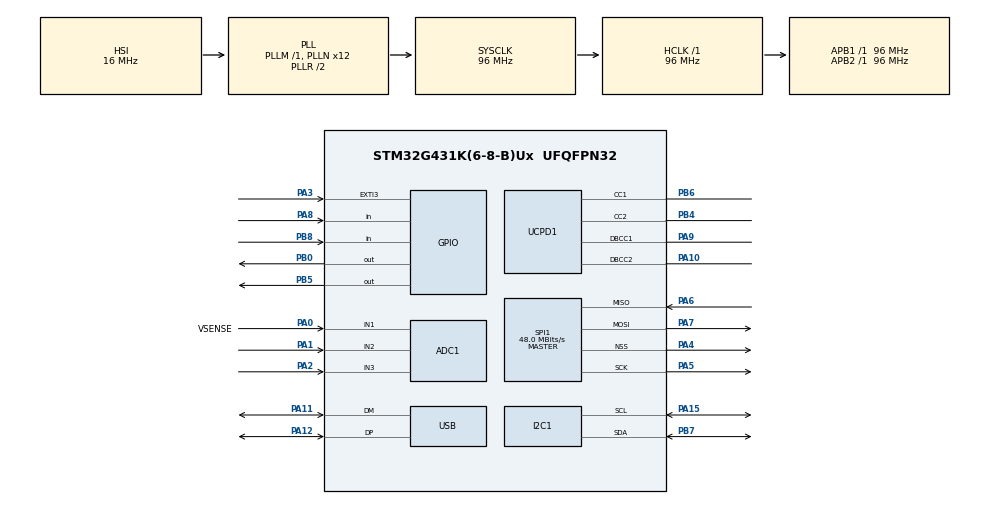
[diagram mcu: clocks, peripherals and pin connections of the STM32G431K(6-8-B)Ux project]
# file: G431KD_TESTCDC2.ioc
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ADC1.Channel-0\#ChannelRegularConversion=ADC_CHANNEL_1
ADC1.ClockPrescaler=ADC_CLOCK_SYNC_PCLK_DIV4
ADC1.ContinuousConvMode=ENABLE
ADC1.NbrOfConversion=1
ADC1.NbrOfConversionFlag=1
ADC1.OffsetNumber-0\#ChannelRegularConversion=ADC_OFFSET_NONE
ADC1.Overrun=ADC_OVR_DATA_OVERWRITTEN
ADC1.Rank-0\#ChannelRegularConversion=1
ADC1.SamplingTime-0\#ChannelRegularConversion=ADC_SAMPLETIME_247CYCLES_5
ADC1.master=1
Dma.ADC1.0.Direction=DMA_PERIPH_TO_MEMORY
Dma.ADC1.0.EventEnable=DISABLE
Dma.ADC1.0.Instance=DMA1_Channel3
Dma.ADC1.0.MemDataAlignment=DMA_MDATAALIGN_HALFWORD
Dma.ADC1.0.MemInc=DMA_MINC_ENABLE
Dma.ADC1.0.Mode=DMA_NORMAL
Dma.ADC1.0.PeriphDataAlignment=DMA_PDATAALIGN_HALFWORD
Dma.ADC1.0.PeriphInc=DMA_PINC_DISABLE
Dma.ADC1.0.Polarity=HAL_DMAMUX_REQ_GEN_RISING
Dma.ADC1.0.Priority=DMA_PRIORITY_LOW
Dma.ADC1.0.RequestNumber=1
Dma.ADC1.0.SignalID=NONE
Dma.ADC1.0.SyncEnable=DISABLE
Dma.ADC1.0.SyncPolarity=HAL_DMAMUX_SYNC_NO_EVENT
Dma.ADC1.0.SyncRequestNumber=1
Dma.ADC1.0.SyncSignalID=NONE
Dma.I2C1_RX.5.Direction=DMA_PERIPH_TO_MEMORY
Dma.I2C1_RX.5.EventEnable=DISABLE
Dma.I2C1_RX.5.Instance=DMA2_Channel1
Dma.I2C1_RX.5.MemDataAlignment=DMA_MDATAALIGN_BYTE
Dma.I2C1_RX.5.MemInc=DMA_MINC_ENABLE
Dma.I2C1_RX.5.Mode=DMA_NORMAL
Dma.I2C1_RX.5.PeriphDataAlignment=DMA_PDATAALIGN_BYTE
Dma.I2C1_RX.5.PeriphInc=DMA_PINC_DISABLE
Dma.I2C1_RX.5.Polarity=HAL_DMAMUX_REQ_GEN_RISING
Dma.I2C1_RX.5.Priority=DMA_PRIORITY_LOW
Dma.I2C1_RX.5.RequestNumber=1
Dma.I2C1_RX.5.SignalID=NONE
Dma.I2C1_RX.5.SyncEnable=DISABLE
Dma.I2C1_RX.5.SyncPolarity=HAL_DMAMUX_SYNC_NO_EVENT
Dma.I2C1_RX.5.SyncRequestNumber=1
Dma.I2C1_RX.5.SyncSignalID=NONE
Dma.I2C1_TX.6.Direction=DMA_MEMORY_TO_PERIPH
Dma.I2C1_TX.6.EventEnable=DISABLE
Dma.I2C1_TX.6.Instance=DMA2_Channel2
Dma.I2C1_TX.6.MemDataAlignment=DMA_MDATAALIGN_BYTE
Dma.I2C1_TX.6.MemInc=DMA_MINC_ENABLE
Dma.I2C1_TX.6.Mode=DMA_NORMAL
Dma.I2C1_TX.6.PeriphDataAlignment=DMA_PDATAALIGN_BYTE
Dma.I2C1_TX.6.PeriphInc=DMA_PINC_DISABLE
Dma.I2C1_TX.6.Polarity=HAL_DMAMUX_REQ_GEN_RISING
Dma.I2C1_TX.6.Priority=DMA_PRIORITY_LOW
Dma.I2C1_TX.6.RequestNumber=1
Dma.I2C1_TX.6.SignalID=NONE
Dma.I2C1_TX.6.SyncEnable=DISABLE
Dma.I2C1_TX.6.SyncPolarity=HAL_DMAMUX_SYNC_NO_EVENT
Dma.I2C1_TX.6.SyncRequestNumber=1
Dma.I2C1_TX.6.SyncSignalID=NONE
Dma.Request0=ADC1
Dma.Request1=UCPD1_RX
Dma.Request2=UCPD1_TX
Dma.Request3=SPI1_RX
Dma.Request4=SPI1_TX
Dma.Request5=I2C1_RX
Dma.Request6=I2C1_TX
Dma.SPI1_RX.3.Direction=DMA_PERIPH_TO_MEMORY
Dma.SPI1_RX.3.EventEnable=DISABLE
Dma.SPI1_RX.3.Instance=DMA1_Channel4
Dma.SPI1_RX.3.MemDataAlignment=DMA_MDATAALIGN_BYTE
Dma.SPI1_RX.3.MemInc=DMA_MINC_ENABLE
Dma.SPI1_RX.3.Mode=DMA_NORMAL
Dma.SPI1_RX.3.PeriphDataAlignment=DMA_PDATAALIGN_BYTE
Dma.SPI1_RX.3.PeriphInc=DMA_PINC_DISABLE
Dma.SPI1_RX.3.Polarity=HAL_DMAMUX_REQ_GEN_RISING
Dma.SPI1_RX.3.Priority=DMA_PRIORITY_LOW
Dma.SPI1_RX.3.RequestNumber=1
Dma.SPI1_RX.3.SignalID=NONE
Dma.SPI1_RX.3.SyncEnable=DISABLE
Dma.SPI1_RX.3.SyncPolarity=HAL_DMAMUX_SYNC_NO_EVENT
Dma.SPI1_RX.3.SyncRequestNumber=1
Dma.SPI1_RX.3.SyncSignalID=NONE
Dma.SPI1_TX.4.Direction=DMA_MEMORY_TO_PERIPH
Dma.SPI1_TX.4.EventEnable=DISABLE
Dma.SPI1_TX.4.Instance=DMA1_Channel5
Dma.SPI1_TX.4.MemDataAlignment=DMA_MDATAALIGN_BYTE
Dma.SPI1_TX.4.MemInc=DMA_MINC_ENABLE
Dma.SPI1_TX.4.Mode=DMA_NORMAL
Dma.SPI1_TX.4.PeriphDataAlignment=DMA_PDATAALIGN_BYTE
Dma.SPI1_TX.4.PeriphInc=DMA_PINC_DISABLE
Dma.SPI1_TX.4.Polarity=HAL_DMAMUX_REQ_GEN_RISING
Dma.SPI1_TX.4.Priority=DMA_PRIORITY_LOW
Dma.SPI1_TX.4.RequestNumber=1
Dma.SPI1_TX.4.SignalID=NONE
Dma.SPI1_TX.4.SyncEnable=DISABLE
Dma.SPI1_TX.4.SyncPolarity=HAL_DMAMUX_SYNC_NO_EVENT
Dma.SPI1_TX.4.SyncRequestNumber=1
Dma.SPI1_TX.4.SyncSignalID=NONE
Dma.UCPD1_RX.1.Direction=DMA_PERIPH_TO_MEMORY
Dma.UCPD1_RX.1.EventEnable=DISABLE
Dma.UCPD1_RX.1.Instance=DMA1_Channel1
Dma.UCPD1_RX.1.MemDataAlignment=DMA_MDATAALIGN_BYTE
Dma.UCPD1_RX.1.MemInc=DMA_MINC_ENABLE
Dma.UCPD1_RX.1.Mode=DMA_NORMAL
Dma.UCPD1_RX.1.PeriphDataAlignment=DMA_PDATAALIGN_BYTE
Dma.UCPD1_RX.1.PeriphInc=DMA_PINC_DISABLE
Dma.UCPD1_RX.1.Polarity=HAL_DMAMUX_REQ_GEN_RISING
Dma.UCPD1_RX.1.Priority=DMA_PRIORITY_LOW
Dma.UCPD1_RX.1.RequestNumber=1
Dma.UCPD1_RX.1.SignalID=NONE
Dma.UCPD1_RX.1.SyncEnable=DISABLE
Dma.UCPD1_RX.1.SyncPolarity=HAL_DMAMUX_SYNC_NO_EVENT
Dma.UCPD1_RX.1.SyncRequestNumber=1
Dma.UCPD1_RX.1.SyncSignalID=NONE
Dma.UCPD1_TX.2.Direction=DMA_MEMORY_TO_PERIPH
Dma.UCPD1_TX.2.EventEnable=DISABLE
Dma.UCPD1_TX.2.Instance=DMA1_Channel2
Dma.UCPD1_TX.2.MemDataAlignment=DMA_MDATAALIGN_BYTE
Dma.UCPD1_TX.2.MemInc=DMA_MINC_ENABLE
Dma.UCPD1_TX.2.Mode=DMA_NORMAL
Dma.UCPD1_TX.2.PeriphDataAlignment=DMA_PDATAALIGN_BYTE
Dma.UCPD1_TX.2.PeriphInc=DMA_PINC_DISABLE
Dma.UCPD1_TX.2.Polarity=HAL_DMAMUX_REQ_GEN_RISING
Dma.UCPD1_TX.2.Priority=DMA_PRIORITY_LOW
Dma.UCPD1_TX.2.RequestNumber=1
Dma.UCPD1_TX.2.SignalID=NONE
Dma.UCPD1_TX.2.SyncEnable=DISABLE
Dma.UCPD1_TX.2.SyncPolarity=HAL_DMAMUX_SYNC_NO_EVENT
Dma.UCPD1_TX.2.SyncRequestNumber=1
Dma.UCPD1_TX.2.SyncSignalID=NONE
FREERTOS.Tasks01=defaultTask,24,128,StartDefaultTask,Default,NULL,Dynamic,NULL,NULL
FREERTOS.configTOTAL_HEAP_SIZE=0x1000
I2C1.Timing=0x10B0DCFB
Mcu.Family=STM32G4
Mcu.Name=STM32G431K(6-8-B)Ux
Mcu.Package=UFQFPN32
Mcu.UserConstants=VDDA_APPLI,3300
NVIC.DMA1_Channel1_IRQn=true\:0\:0\:false\:false\:true\:true\:false\:true
NVIC.DMA1_Channel2_IRQn=true\:0\:0\:false\:false\:true\:true\:false\:true
NVIC.DMA1_Channel3_IRQn=true\:0\:0\:false\:false\:true\:true\:false\:true
NVIC.DMA1_Channel4_IRQn=true\:0\:0\:false\:false\:true\:true\:false\:true
NVIC.DMA1_Channel5_IRQn=true\:0\:0\:false\:false\:true\:true\:false\:true
NVIC.DMA2_Channel1_IRQn=true\:0\:0\:false\:false\:true\:false\:false\:true
NVIC.DMA2_Channel2_IRQn=true\:0\:0\:false\:false\:true\:false\:false\:true
NVIC.PriorityGroup=NVIC_PRIORITYGROUP_4
NVIC.TIM8_UP_IRQn=true\:0\:0\:false\:false\:true\:false\:false\:true
NVIC.TimeBase=TIM8_UP_IRQn
NVIC.TimeBaseIP=TIM8
NVIC.UCPD1_IRQn=true\:0\:0\:false\:false\:true\:true\:true\:false
NVIC.USB_LP_IRQn=true\:0\:0\:false\:false\:true\:false\:false\:true
PA0.GPIO_Label=VSENSE
PA0.Mode=IN1-Single-Ended
PA0.Signal=ADC1_IN1
PA1.Mode=IN2-Single-Ended
PA1.Signal=ADC1_IN2
PA10.Mode=EnableDeadBattery
PA10.Signal=UCPD1_DBCC2
PA11.Mode=Device
PA11.Signal=USB_DM
PA12.Mode=Device
PA12.Signal=USB_DP
PA13.Mode=Trace_Asynchronous_SW
PA13.Signal=SYS_JTMS-SWDIO
PA14.Mode=Trace_Asynchronous_SW
PA14.Signal=SYS_JTCK-SWCLK
PA15.Mode=I2C
PA15.Signal=I2C1_SCL
PA2.Mode=IN3-Single-Ended
PA2.Signal=ADC1_IN3
PA3.Signal=GPXTI3
PA4.Mode=NSS_Signal_Hard_Output
PA4.Signal=SPI1_NSS
PA5.Mode=Full_Duplex_Master
PA5.Signal=SPI1_SCK
PA6.Mode=Full_Duplex_Master
PA6.Signal=SPI1_MISO
PA7.Mode=Full_Duplex_Master
PA7.Signal=SPI1_MOSI
PA8.GPIO_PuPd=GPIO_PULLUP
PA8.Signal=GPIO_Input
PA9.Mode=EnableDeadBattery
PA9.Signal=UCPD1_DBCC1
PB0.Signal=GPIO_Output
PB3.Mode=Trace_Asynchronous_SW
PB3.Signal=SYS_JTDO-SWO
PB4.Mode=Sink_AllSignals
PB4.Signal=UCPD1_CC2
PB5.Signal=GPIO_Output
PB6.Mode=Sink_AllSignals
PB6.Signal=UCPD1_CC1
PB7.Mode=I2C
PB7.Signal=I2C1_SDA
PB8-BOOT0.GPIO_PuPd=GPIO_PULLUP
PB8-BOOT0.Signal=GPIO_Input
PF0-OSC_IN.Mode=HSE-External-Oscillator
PF0-OSC_IN.Signal=RCC_OSC_IN
PF1-OSC_OUT.Mode=HSE-External-Oscillator
PF1-OSC_OUT.Signal=RCC_OSC_OUT
ProjectManager.HeapSize=0x400
ProjectManager.StackSize=0x400
ProjectManager.TargetToolchain=STM32CubeIDE
RCC.ADC12Freq_Value=96000000
RCC.AHBFreq_Value=96000000
RCC.APB1Freq_Value=96000000
RCC.APB1TimFreq_Value=96000000
RCC.APB2Freq_Value=96000000
RCC.APB2TimFreq_Value=96000000
RCC.CK48CLockSelection=RCC_USBCLKSOURCE_HSI48
RCC.CortexFreq_Value=96000000
RCC.EXTERNAL_CLOCK_VALUE=12288000
RCC.HCLKFreq_Value=96000000
RCC.HSE_VALUE=24000000
RCC.HSI48_VALUE=48000000
RCC.HSI_VALUE=16000000
RCC.LSE_VALUE=32768
RCC.PLLN=12
RCC.PLLQ=RCC_PLLQ_DIV4
RCC.SYSCLKFreq_VALUE=96000000
RCC.SYSCLKSource=RCC_SYSCLKSOURCE_PLLCLK
RCC.USBFreq_Value=48000000
RCC.VCOOutputFreq_Value=192000000
SPI1.BaudRatePrescaler=SPI_BAUDRATEPRESCALER_2
SPI1.CalculateBaudRate=48.0 MBits/s
SPI1.Direction=SPI_DIRECTION_2LINES
SPI1.Mode=SPI_MODE_MASTER
SPI1.VirtualNSS=VM_NSSHARD
SPI1.VirtualType=VM_MASTER
USBPD.PE_SpecRevision_P0=USBPD_SPECIFICATION_REV3
USBPD.PE_SupportedSOPapos_P0=USBPD_SUPPORTED_SOP_SOP1
USBPD.PORT0_SINK_PDO1=0x02019096
USB_DEVICE.CLASS_NAME_FS=CDC
USB_DEVICE.PID_CDC_FS=0x5740
USB_DEVICE.USBD_DEBUG_LEVEL=3
USB_DEVICE.USBD_MAX_NUM_CONFIGURATION=1
USB_DEVICE.USBD_MAX_NUM_INTERFACES=1
USB_DEVICE.VID=0x483
USB_DEVICE.VirtualMode=Cdc
USB_DEVICE.VirtualModeFS=Cdc_FS
VP_ADC1_TempSens_Input.Mode=IN-TempSens
VP_FREERTOS_VS_CMSIS_V2.Mode=CMSIS_V2
VP_RTC_VS_RTC_Activate.Mode=RTC_Enabled
VP_SYS_VS_DBSignals.Mode=DisableDeadBatterySignals
VP_SYS_VS_tim8.Mode=TIM8
VP_SYS_V_PVD_IN.Mode=Mode_PVD_Int
VP_USBPD_VS_PD3MINSNK.Mode=PD3_Min_Snk
VP_USBPD_VS_USBPD1.Mode=USBPD_P0
VP_USBPD_VS_usbpd_tim1.Mode=TIM1
VP_USB_DEVICE_VS_USB_DEVICE_CDC_FS.Mode=CDC_FS
board=custom

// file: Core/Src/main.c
/* USER CODE BEGIN Header */
/**
  ******************************************************************************
  * @file           : main.c
  * @brief          : Main program body
  ******************************************************************************
  * @attention
  *
  * <h2><center>&copy; Copyright (c) 2020 STMicroelectronics.
  * All rights reserved.</center></h2>
  *
  * This software component is licensed by ST under Ultimate Liberty license
  * SLA0044, the "License"; You may not use this file except in compliance with
  * the License. You may obtain a copy of the License at:
  *                             www.st.com/SLA0044
  *
  ******************************************************************************
  */
/* USER CODE END Header */
#include "main.h"
#include "cmsis_os.h"
#include "usbpd.h"
#include "usb_device.h"

/* USER CODE BEGIN Includes */
// https://github.com/AlexKlimaj/LiPow-Firmware
// PD User manual: UM2552
// https://github.com/STMicroelectronics/STM32CubeG4/blob/master/Projects/STM32G474E-EVAL/Applications/USB-PD/USB-PD_Provider_1port/Src/usbpd_vdm_user.c
// https://github.com/STMicroelectronics/STM32CubeG4/blob/master/Projects/STM32G474E-EVAL/Demonstrations/Modules/ucpd/usbpd_dpm_user.h
/* USER CODE END Includes */

ADC_HandleTypeDef hadc1;
DMA_HandleTypeDef hdma_adc1;

I2C_HandleTypeDef hi2c1;
DMA_HandleTypeDef hdma_i2c1_rx;
DMA_HandleTypeDef hdma_i2c1_tx;

RTC_HandleTypeDef hrtc;

SPI_HandleTypeDef hspi1;
DMA_HandleTypeDef hdma_spi1_rx;
DMA_HandleTypeDef hdma_spi1_tx;

/* Definitions for defaultTask */
osThreadId_t defaultTaskHandle;
const osThreadAttr_t defaultTask_attributes = {
  .name = "defaultTask",
  .priority = (osPriority_t) osPriorityNormal,
  .stack_size = 128 * 4
};

void SystemClock_Config(void);
static void MX_GPIO_Init(void);
static void MX_DMA_Init(void);
static void MX_ADC1_Init(void);
static void MX_UCPD1_Init(void);
static void MX_SPI1_Init(void);
static void MX_I2C1_Init(void);
static void MX_RTC_Init(void);
void StartDefaultTask(void *argument);

int main(void)
{

  /* MCU Configuration--------------------------------------------------------*/

  /* Reset of all peripherals, Initializes the Flash interface and the Systick. */
  HAL_Init();

  /* Configure the system clock */
  SystemClock_Config();

  /* Initialize all configured peripherals */
  MX_GPIO_Init();
  MX_DMA_Init();
  MX_ADC1_Init();
  MX_UCPD1_Init();
  MX_SPI1_Init();
  MX_I2C1_Init();
  MX_RTC_Init();
  MX_USB_Device_Init();

  /* Init scheduler */
  osKernelInitialize();
  /* USBPD initialisation ---------------------------------*/
  MX_USBPD_Init();

  /* Create the thread(s) */
  /* creation of defaultTask */
  defaultTaskHandle = osThreadNew(StartDefaultTask, NULL, &defaultTask_attributes);

  /* Start scheduler */
  osKernelStart();

  /* We should never get here as control is now taken by the scheduler */
  /* Infinite loop */
  while (1)
  {

  }
}

void SystemClock_Config(void)
{
  RCC_OscInitTypeDef RCC_OscInitStruct = {0};
  RCC_ClkInitTypeDef RCC_ClkInitStruct = {0};
  RCC_PeriphCLKInitTypeDef PeriphClkInit = {0};

  /** Configure the main internal regulator output voltage
  */
  HAL_PWREx_ControlVoltageScaling(PWR_REGULATOR_VOLTAGE_SCALE1);
  /** Initializes the RCC Oscillators according to the specified parameters
  * in the RCC_OscInitTypeDef structure.
  */
  RCC_OscInitStruct.OscillatorType = RCC_OSCILLATORTYPE_HSI|RCC_OSCILLATORTYPE_HSI48
                              |RCC_OSCILLATORTYPE_LSI;
  RCC_OscInitStruct.HSIState = RCC_HSI_ON;
  RCC_OscInitStruct.HSICalibrationValue = RCC_HSICALIBRATION_DEFAULT;
  RCC_OscInitStruct.LSIState = RCC_LSI_ON;
  RCC_OscInitStruct.HSI48State = RCC_HSI48_ON;
  RCC_OscInitStruct.PLL.PLLState = RCC_PLL_ON;
  RCC_OscInitStruct.PLL.PLLSource = RCC_PLLSOURCE_HSI;
  RCC_OscInitStruct.PLL.PLLM = RCC_PLLM_DIV1;
  RCC_OscInitStruct.PLL.PLLN = 12;
  RCC_OscInitStruct.PLL.PLLP = RCC_PLLP_DIV2;
  RCC_OscInitStruct.PLL.PLLQ = RCC_PLLQ_DIV4;
  RCC_OscInitStruct.PLL.PLLR = RCC_PLLR_DIV2;
  if (HAL_RCC_OscConfig(&RCC_OscInitStruct) != HAL_OK)
  {
    Error_Handler();
  }
  /** Initializes the CPU, AHB and APB buses clocks
  */
  RCC_ClkInitStruct.ClockType = RCC_CLOCKTYPE_HCLK|RCC_CLOCKTYPE_SYSCLK
                              |RCC_CLOCKTYPE_PCLK1|RCC_CLOCKTYPE_PCLK2;
  RCC_ClkInitStruct.SYSCLKSource = RCC_SYSCLKSOURCE_PLLCLK;
  RCC_ClkInitStruct.AHBCLKDivider = RCC_SYSCLK_DIV1;
  RCC_ClkInitStruct.APB1CLKDivider = RCC_HCLK_DIV1;
  RCC_ClkInitStruct.APB2CLKDivider = RCC_HCLK_DIV1;

  if (HAL_RCC_ClockConfig(&RCC_ClkInitStruct, FLASH_LATENCY_2) != HAL_OK)
  {
    Error_Handler();
  }
  /** Initializes the peripherals clocks
  */
  PeriphClkInit.PeriphClockSelection = RCC_PERIPHCLK_RTC|RCC_PERIPHCLK_I2C1
                              |RCC_PERIPHCLK_USB|RCC_PERIPHCLK_ADC12;
  PeriphClkInit.I2c1ClockSelection = RCC_I2C1CLKSOURCE_PCLK1;
  PeriphClkInit.UsbClockSelection = RCC_USBCLKSOURCE_HSI48;
  PeriphClkInit.Adc12ClockSelection = RCC_ADC12CLKSOURCE_SYSCLK;
  PeriphClkInit.RTCClockSelection = RCC_RTCCLKSOURCE_LSI;

  if (HAL_RCCEx_PeriphCLKConfig(&PeriphClkInit) != HAL_OK)
  {
    Error_Handler();
  }
}

static void MX_ADC1_Init(void)
{

  ADC_MultiModeTypeDef multimode = {0};
  ADC_ChannelConfTypeDef sConfig = {0};

  /** Common config
  */
  hadc1.Instance = ADC1;
  hadc1.Init.ClockPrescaler = ADC_CLOCK_SYNC_PCLK_DIV4;
  hadc1.Init.Resolution = ADC_RESOLUTION_12B;
  hadc1.Init.DataAlign = ADC_DATAALIGN_RIGHT;
  hadc1.Init.GainCompensation = 0;
  hadc1.Init.ScanConvMode = ADC_SCAN_DISABLE;
  hadc1.Init.EOCSelection = ADC_EOC_SINGLE_CONV;
  hadc1.Init.LowPowerAutoWait = DISABLE;
  hadc1.Init.ContinuousConvMode = ENABLE;
  hadc1.Init.NbrOfConversion = 1;
  hadc1.Init.DiscontinuousConvMode = DISABLE;
  hadc1.Init.ExternalTrigConv = ADC_SOFTWARE_START;
  hadc1.Init.ExternalTrigConvEdge = ADC_EXTERNALTRIGCONVEDGE_NONE;
  hadc1.Init.DMAContinuousRequests = DISABLE;
  hadc1.Init.Overrun = ADC_OVR_DATA_OVERWRITTEN;
  hadc1.Init.OversamplingMode = DISABLE;
  if (HAL_ADC_Init(&hadc1) != HAL_OK)
  {
    Error_Handler();
  }
  /** Configure the ADC multi-mode
  */
  multimode.Mode = ADC_MODE_INDEPENDENT;
  if (HAL_ADCEx_MultiModeConfigChannel(&hadc1, &multimode) != HAL_OK)
  {
    Error_Handler();
  }
  /** Configure Regular Channel
  */
  sConfig.Channel = ADC_CHANNEL_1;
  sConfig.Rank = ADC_REGULAR_RANK_1;
  sConfig.SamplingTime = ADC_SAMPLETIME_247CYCLES_5;
  sConfig.SingleDiff = ADC_SINGLE_ENDED;
  sConfig.OffsetNumber = ADC_OFFSET_NONE;
  sConfig.Offset = 0;
  if (HAL_ADC_ConfigChannel(&hadc1, &sConfig) != HAL_OK)
  {
    Error_Handler();
  }

}

static void MX_I2C1_Init(void)
{

  hi2c1.Instance = I2C1;
  hi2c1.Init.Timing = 0x10B0DCFB;
  hi2c1.Init.OwnAddress1 = 0;
  hi2c1.Init.AddressingMode = I2C_ADDRESSINGMODE_7BIT;
  hi2c1.Init.DualAddressMode = I2C_DUALADDRESS_DISABLE;
  hi2c1.Init.OwnAddress2 = 0;
  hi2c1.Init.OwnAddress2Masks = I2C_OA2_NOMASK;
  hi2c1.Init.GeneralCallMode = I2C_GENERALCALL_DISABLE;
  hi2c1.Init.NoStretchMode = I2C_NOSTRETCH_DISABLE;
  if (HAL_I2C_Init(&hi2c1) != HAL_OK)
  {
    Error_Handler();
  }
  /** Configure Analogue filter
  */
  if (HAL_I2CEx_ConfigAnalogFilter(&hi2c1, I2C_ANALOGFILTER_ENABLE) != HAL_OK)
  {
    Error_Handler();
  }
  /** Configure Digital filter
  */
  if (HAL_I2CEx_ConfigDigitalFilter(&hi2c1, 0) != HAL_OK)
  {
    Error_Handler();
  }

}

static void MX_RTC_Init(void)
{

  /** Initialize RTC Only
  */
  hrtc.Instance = RTC;
  hrtc.Init.HourFormat = RTC_HOURFORMAT_24;
  hrtc.Init.AsynchPrediv = 127;
  hrtc.Init.SynchPrediv = 255;
  hrtc.Init.OutPut = RTC_OUTPUT_DISABLE;
  hrtc.Init.OutPutRemap = RTC_OUTPUT_REMAP_NONE;
  hrtc.Init.OutPutPolarity = RTC_OUTPUT_POLARITY_HIGH;
  hrtc.Init.OutPutType = RTC_OUTPUT_TYPE_OPENDRAIN;
  hrtc.Init.OutPutPullUp = RTC_OUTPUT_PULLUP_NONE;
  if (HAL_RTC_Init(&hrtc) != HAL_OK)
  {
    Error_Handler();
  }

}

static void MX_SPI1_Init(void)
{

  /* SPI1 parameter configuration*/
  hspi1.Instance = SPI1;
  hspi1.Init.Mode = SPI_MODE_MASTER;
  hspi1.Init.Direction = SPI_DIRECTION_2LINES;
  hspi1.Init.DataSize = SPI_DATASIZE_4BIT;
  hspi1.Init.CLKPolarity = SPI_POLARITY_LOW;
  hspi1.Init.CLKPhase = SPI_PHASE_1EDGE;
  hspi1.Init.NSS = SPI_NSS_HARD_OUTPUT;
  hspi1.Init.BaudRatePrescaler = SPI_BAUDRATEPRESCALER_2;
  hspi1.Init.FirstBit = SPI_FIRSTBIT_MSB;
  hspi1.Init.TIMode = SPI_TIMODE_DISABLE;
  hspi1.Init.CRCCalculation = SPI_CRCCALCULATION_DISABLE;
  hspi1.Init.CRCPolynomial = 7;
  hspi1.Init.CRCLength = SPI_CRC_LENGTH_DATASIZE;
  hspi1.Init.NSSPMode = SPI_NSS_PULSE_ENABLE;
  if (HAL_SPI_Init(&hspi1) != HAL_OK)
  {
    Error_Handler();
  }

}

static void MX_UCPD1_Init(void)
{

  LL_GPIO_InitTypeDef GPIO_InitStruct = {0};

  /* Peripheral clock enable */
  LL_APB1_GRP2_EnableClock(LL_APB1_GRP2_PERIPH_UCPD1);

  LL_AHB2_GRP1_EnableClock(LL_AHB2_GRP1_PERIPH_GPIOB);
  /**UCPD1 GPIO Configuration
  PB4   ------> UCPD1_CC2
  PB6   ------> UCPD1_CC1
  */
  GPIO_InitStruct.Pin = LL_GPIO_PIN_4;
  GPIO_InitStruct.Mode = LL_GPIO_MODE_ANALOG;
  GPIO_InitStruct.Pull = LL_GPIO_PULL_NO;
  LL_GPIO_Init(GPIOB, &GPIO_InitStruct);

  GPIO_InitStruct.Pin = LL_GPIO_PIN_6;
  GPIO_InitStruct.Mode = LL_GPIO_MODE_ANALOG;
  GPIO_InitStruct.Pull = LL_GPIO_PULL_NO;
  LL_GPIO_Init(GPIOB, &GPIO_InitStruct);

  /* UCPD1 DMA Init */

  /* UCPD1_RX Init */
  LL_DMA_SetPeriphRequest(DMA1, LL_DMA_CHANNEL_1, LL_DMAMUX_REQ_UCPD1_RX);

  LL_DMA_SetDataTransferDirection(DMA1, LL_DMA_CHANNEL_1, LL_DMA_DIRECTION_PERIPH_TO_MEMORY);

  LL_DMA_SetChannelPriorityLevel(DMA1, LL_DMA_CHANNEL_1, LL_DMA_PRIORITY_LOW);

  LL_DMA_SetMode(DMA1, LL_DMA_CHANNEL_1, LL_DMA_MODE_NORMAL);

  LL_DMA_SetPeriphIncMode(DMA1, LL_DMA_CHANNEL_1, LL_DMA_PERIPH_NOINCREMENT);

  LL_DMA_SetMemoryIncMode(DMA1, LL_DMA_CHANNEL_1, LL_DMA_MEMORY_INCREMENT);

  LL_DMA_SetPeriphSize(DMA1, LL_DMA_CHANNEL_1, LL_DMA_PDATAALIGN_BYTE);

  LL_DMA_SetMemorySize(DMA1, LL_DMA_CHANNEL_1, LL_DMA_MDATAALIGN_BYTE);

  /* UCPD1_TX Init */
  LL_DMA_SetPeriphRequest(DMA1, LL_DMA_CHANNEL_2, LL_DMAMUX_REQ_UCPD1_TX);

  LL_DMA_SetDataTransferDirection(DMA1, LL_DMA_CHANNEL_2, LL_DMA_DIRECTION_MEMORY_TO_PERIPH);

  LL_DMA_SetChannelPriorityLevel(DMA1, LL_DMA_CHANNEL_2, LL_DMA_PRIORITY_LOW);

  LL_DMA_SetMode(DMA1, LL_DMA_CHANNEL_2, LL_DMA_MODE_NORMAL);

  LL_DMA_SetPeriphIncMode(DMA1, LL_DMA_CHANNEL_2, LL_DMA_PERIPH_NOINCREMENT);

  LL_DMA_SetMemoryIncMode(DMA1, LL_DMA_CHANNEL_2, LL_DMA_MEMORY_INCREMENT);

  LL_DMA_SetPeriphSize(DMA1, LL_DMA_CHANNEL_2, LL_DMA_PDATAALIGN_BYTE);

  LL_DMA_SetMemorySize(DMA1, LL_DMA_CHANNEL_2, LL_DMA_MDATAALIGN_BYTE);

  /* UCPD1 interrupt Init */
  NVIC_SetPriority(UCPD1_IRQn, NVIC_EncodePriority(NVIC_GetPriorityGrouping(),0, 0));
  NVIC_EnableIRQ(UCPD1_IRQn);

}

static void MX_DMA_Init(void)
{

  /* DMA controller clock enable */
  __HAL_RCC_DMAMUX1_CLK_ENABLE();
  __HAL_RCC_DMA1_CLK_ENABLE();
  __HAL_RCC_DMA2_CLK_ENABLE();

  /* DMA interrupt init */
  /* DMA1_Channel1_IRQn interrupt configuration */
  NVIC_SetPriority(DMA1_Channel1_IRQn, NVIC_EncodePriority(NVIC_GetPriorityGrouping(),0, 0));
  NVIC_EnableIRQ(DMA1_Channel1_IRQn);
  /* DMA1_Channel2_IRQn interrupt configuration */
  NVIC_SetPriority(DMA1_Channel2_IRQn, NVIC_EncodePriority(NVIC_GetPriorityGrouping(),0, 0));
  NVIC_EnableIRQ(DMA1_Channel2_IRQn);
  /* DMA1_Channel3_IRQn interrupt configuration */
  HAL_NVIC_SetPriority(DMA1_Channel3_IRQn, 0, 0);
  HAL_NVIC_EnableIRQ(DMA1_Channel3_IRQn);
  /* DMA1_Channel4_IRQn interrupt configuration */
  HAL_NVIC_SetPriority(DMA1_Channel4_IRQn, 0, 0);
  HAL_NVIC_EnableIRQ(DMA1_Channel4_IRQn);
  /* DMA1_Channel5_IRQn interrupt configuration */
  HAL_NVIC_SetPriority(DMA1_Channel5_IRQn, 0, 0);
  HAL_NVIC_EnableIRQ(DMA1_Channel5_IRQn);
  /* DMA2_Channel1_IRQn interrupt configuration */
  HAL_NVIC_SetPriority(DMA2_Channel1_IRQn, 0, 0);
  HAL_NVIC_EnableIRQ(DMA2_Channel1_IRQn);
  /* DMA2_Channel2_IRQn interrupt configuration */
  HAL_NVIC_SetPriority(DMA2_Channel2_IRQn, 0, 0);
  HAL_NVIC_EnableIRQ(DMA2_Channel2_IRQn);

}

static void MX_GPIO_Init(void)
{
  GPIO_InitTypeDef GPIO_InitStruct = {0};

  /* GPIO Ports Clock Enable */
  __HAL_RCC_GPIOF_CLK_ENABLE();
  __HAL_RCC_GPIOA_CLK_ENABLE();
  __HAL_RCC_GPIOB_CLK_ENABLE();

  /*Configure GPIO pin Output Level */
  HAL_GPIO_WritePin(GPIOB, GPIO_PIN_0|GPIO_PIN_5, GPIO_PIN_RESET);

  /*Configure GPIO pin : PA3 */
  GPIO_InitStruct.Pin = GPIO_PIN_3;
  GPIO_InitStruct.Mode = GPIO_MODE_IT_RISING;
  GPIO_InitStruct.Pull = GPIO_NOPULL;
  HAL_GPIO_Init(GPIOA, &GPIO_InitStruct);

  /*Configure GPIO pins : PB0 PB5 */
  GPIO_InitStruct.Pin = GPIO_PIN_0|GPIO_PIN_5;
  GPIO_InitStruct.Mode = GPIO_MODE_OUTPUT_PP;
  GPIO_InitStruct.Pull = GPIO_NOPULL;
  GPIO_InitStruct.Speed = GPIO_SPEED_FREQ_LOW;
  HAL_GPIO_Init(GPIOB, &GPIO_InitStruct);

  /*Configure GPIO pin : PA8 */
  GPIO_InitStruct.Pin = GPIO_PIN_8;
  GPIO_InitStruct.Mode = GPIO_MODE_INPUT;
  GPIO_InitStruct.Pull = GPIO_PULLUP;
  HAL_GPIO_Init(GPIOA, &GPIO_InitStruct);

  /*Configure GPIO pin : PB8 */
  GPIO_InitStruct.Pin = GPIO_PIN_8;
  GPIO_InitStruct.Mode = GPIO_MODE_INPUT;
  GPIO_InitStruct.Pull = GPIO_PULLUP;
  HAL_GPIO_Init(GPIOB, &GPIO_InitStruct);

}

void StartDefaultTask(void *argument)
{
  for(;;)
  {
    osDelay(1);
  }
}

void HAL_TIM_PeriodElapsedCallback(TIM_HandleTypeDef *htim)
{
  if (htim->Instance == TIM8) {
    HAL_IncTick();
  }
}

void Error_Handler(void)
{
}

/************************ (C) COPYRIGHT STMicroelectronics *****END OF FILE****/
